VERSION ""

NS_ :

BS_:

BU_: APM CanBlue Car_PC BMS DCDC SCU BRS_ECU

BO_ 3221225472 VECTOR__INDEPENDENT_SIG_MSG: 0 Vector__XXX
 SG_ MASTER_ESA_CheckSum : 0|8@0+ (1,0) [0|255] "" Vector__XXX
 SG_ MASTER_REQ_CheckSum : 0|8@0+ (1,0) [0|255] "" Vector__XXX
 SG_ New_Signal_263 : 0|8@1+ (1,0) [0|0] "" Vector__XXX
 SG_ New_Signal_262 : 0|8@1+ (1,0) [0|0] "" Vector__XXX
 SG_ VehV_a : 0|16@0- (0.001,0) [-32.768|32.767] "" Vector__XXX

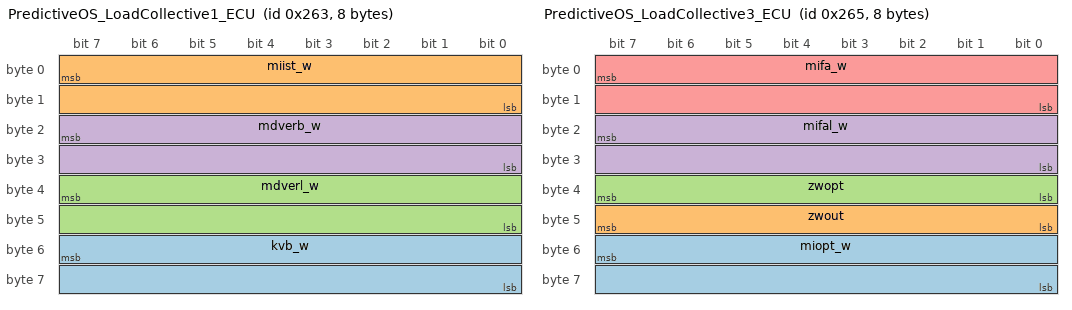
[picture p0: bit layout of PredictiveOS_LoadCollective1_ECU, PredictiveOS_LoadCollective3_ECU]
BO_ 611 PredictiveOS_LoadCollective1_ECU: 8 BRS_ECU
 SG_ kvb_w : 55|16@0+ (0.00390625,0) [0|255.99609375] "" Vector__XXX
 SG_ miist_w : 7|16@0+ (0.00152587890625,0) [0|99.9984741210938] "%" Vector__XXX
 SG_ mdverl_w : 39|16@0+ (0.00152587890625,0) [0|99.9984741210938] "%" Vector__XXX
 SG_ mdverb_w : 23|16@0+ (0.00152587890625,0) [0|99.9984741210938] "%" Vector__XXX

BO_ 384 SAS_180_CAN1: 8 Vector__XXX
 SG_ SAS_SteeringAngle : 7|16@0- (0.1,-780) [-1320|-240] "degree"  BRS_ECU

BO_ 304 ID1_CAN2: 8 Vector__XXX
 SG_ IMU_YawRt : 0|16@1+ (0.005,-163.84) [-163.84|163.84] "degree/s"  BRS_ECU

BO_ 613 PredictiveOS_LoadCollective3_ECU: 8 BRS_ECU
 SG_ miopt_w : 55|16@0+ (0.00152587890625,0) [0|99.9984741210938] "%" Vector__XXX
 SG_ zwout : 47|8@0- (0.75,0) [-96|95.25] "" Vector__XXX
 SG_ zwopt : 39|8@0- (0.75,0) [-96|95.25] "Grad KW" Vector__XXX
 SG_ mifal_w : 23|16@0+ (0.00152587890625,0) [0|99.9984741210938] "%" Vector__XXX
 SG_ mifa_w : 7|16@0+ (0.00152587890625,0) [0|99.9984741210938] "%" Vector__XXX

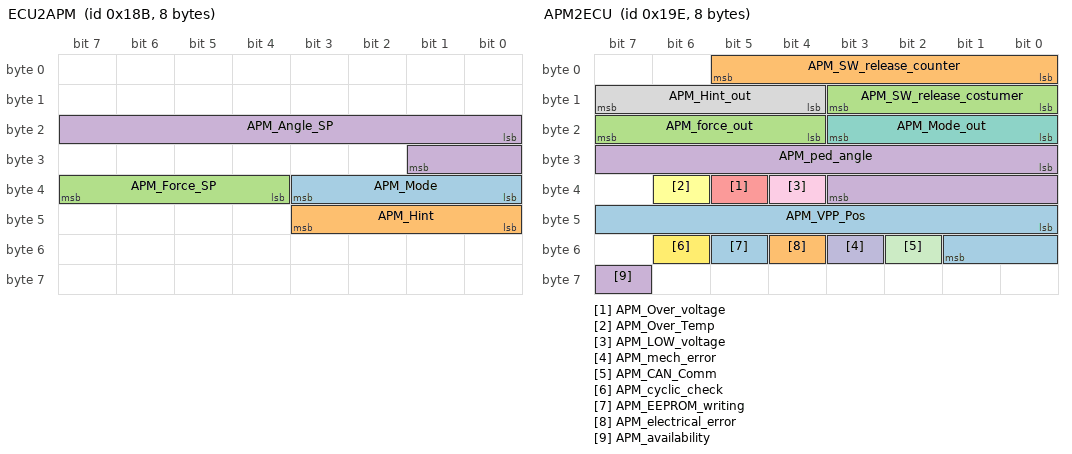
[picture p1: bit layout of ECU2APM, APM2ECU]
BO_ 395 ECU2APM: 8 BRS_ECU
 SG_ APM_Mode : 32|4@1+ (1,0) [0|15] ""  APM
 SG_ APM_Hint : 40|4@1+ (1,0) [0|15] ""  APM
 SG_ APM_Force_SP : 36|4@1+ (2,0) [0|30] "Unit_Newto"  APM
 SG_ APM_Angle_SP : 16|10@1+ (0.13004,-19.89612) [0|100.00076] "Unit_PerCent"  APM

BO_ 414 APM2ECU: 8 APM
 SG_ APM_VPP_Pos : 40|10@1+ (0.13004,-19.89612) [0|100.00076] "Unit_PerCent"  BRS_ECU
 SG_ APM_SW_release_counter : 0|6@1- (1,0) [0|0] ""  BRS_ECU
 SG_ APM_SW_release_costumer : 8|4@1- (1,0) [0|0] ""  BRS_ECU
 SG_ APM_ped_angle : 24|12@1+ (0.03253569,-19.97691366) [0|113.25673689] "Unit_PerCent"  BRS_ECU
 SG_ APM_Over_voltage : 37|1@1+ (1,0) [0|1] ""  BRS_ECU
 SG_ APM_Over_Temp : 38|1@1+ (1,0) [0|1] ""  BRS_ECU
 SG_ APM_Mode_out : 16|4@1+ (1,0) [0|15] ""  BRS_ECU
 SG_ APM_Hint_out : 12|4@1+ (1,0) [0|15] ""  BRS_ECU
 SG_ APM_LOW_voltage : 36|1@1+ (1,0) [0|1] ""  BRS_ECU
 SG_ APM_mech_error : 51|1@1+ (1,0) [0|1] ""  BRS_ECU
 SG_ APM_CAN_Comm : 50|1@1+ (1,0) [0|1] ""  BRS_ECU
 SG_ APM_cyclic_check : 54|1@1+ (1,0) [0|1] ""  BRS_ECU
 SG_ APM_EEPROM_writing : 53|1@1+ (1,0) [0|1] ""  BRS_ECU
 SG_ APM_electrical_error : 52|1@1+ (1,0) [0|1] ""  BRS_ECU
 SG_ APM_force_out : 20|4@1+ (2,0) [0|30] "Unit_Newto"  BRS_ECU
 SG_ APM_availability : 63|1@1+ (1,0) [0|1] ""  BRS_ECU

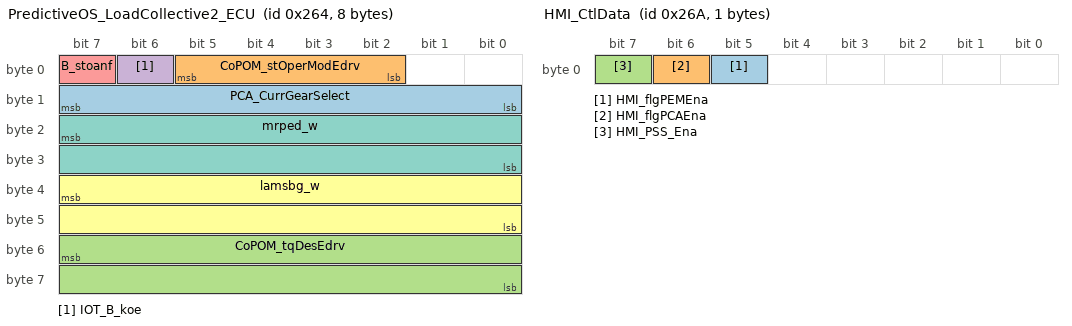
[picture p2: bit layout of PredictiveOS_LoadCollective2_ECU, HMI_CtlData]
BO_ 612 PredictiveOS_LoadCollective2_ECU: 8 BRS_ECU
 SG_ PCA_CurrGearSelect : 15|8@0+ (1,-1) [-1|254] "" Vector__XXX
 SG_ CoPOM_stOperModEdrv : 5|4@0+ (1,0) [0|7] "" Vector__XXX
 SG_ CoPOM_tqDesEdrv : 55|16@0- (0.1,0) [-3276.8|3276.7] "Nm" Vector__XXX
 SG_ IOT_B_koe : 6|1@0+ (1,0) [0|1] "" Vector__XXX
 SG_ B_stoanf : 7|1@0+ (1,0) [0|1] "" Vector__XXX
 SG_ lamsbg_w : 39|16@0+ (0.000244140625,0) [0|15.999755859375] "" Vector__XXX
 SG_ mrped_w : 23|16@0+ (0.0030517578125,0) [0|199.996948242188] "%" Vector__XXX

BO_ 618 HMI_CtlData: 1 CanBlue
 SG_ HMI_flgPEMEna : 5|1@0+ (1,0) [0|1] ""  BRS_ECU
 SG_ HMI_flgPCAEna : 6|1@0+ (1,0) [0|1] ""  BRS_ECU
 SG_ HMI_PSS_Ena : 7|1@0+ (1,0) [0|1] ""  BRS_ECU

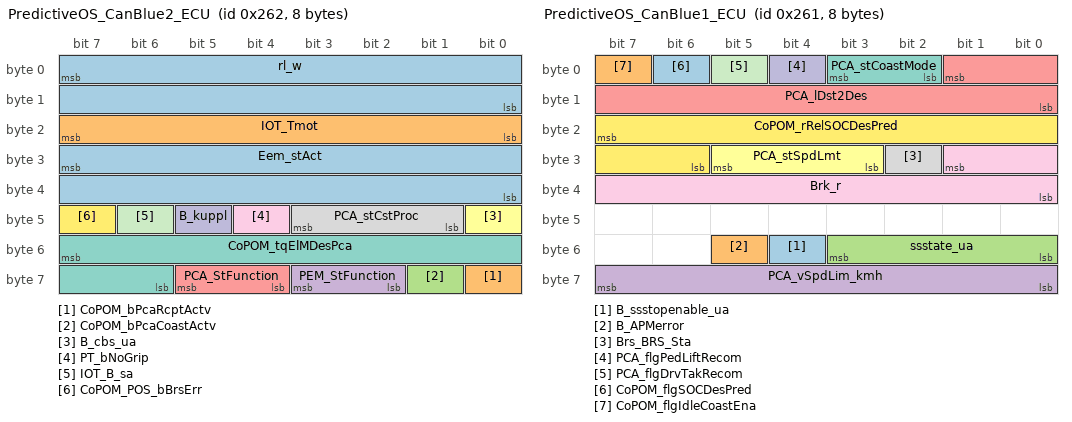
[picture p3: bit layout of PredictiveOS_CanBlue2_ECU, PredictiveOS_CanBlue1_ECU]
BO_ 610 PredictiveOS_CanBlue2_ECU: 8 BRS_ECU
 SG_ rl_w : 7|16@0+ (0.0234375,0) [0|1535.9765625] "%"  CanBlue
 SG_ CoPOM_bPcaRcptActv : 56|1@0+ (1,0) [0|1] ""  CanBlue
 SG_ CoPOM_bPcaCoastActv : 57|1@0+ (1,0) [0|1] ""  CanBlue
 SG_ PEM_StFunction : 59|2@0+ (1,0) [0|3] ""  CanBlue
 SG_ PCA_StFunction : 61|2@0+ (1,0) [0|3] ""  CanBlue
 SG_ B_cbs_ua : 40|1@0+ (1,0) [0|1] ""  CanBlue
 SG_ CoPOM_tqElMDesPca : 55|10@0+ (0.1,-50) [-50|0] ""  CanBlue
 SG_ PCA_stCstProc : 43|3@0+ (1,0) [0|7] ""  CanBlue
 SG_ PT_bNoGrip : 44|1@0+ (1,0) [0|1] ""  CanBlue
 SG_ B_kuppl : 45|1@0+ (1,0) [0|1] ""  CanBlue
 SG_ IOT_B_sa : 46|1@0+ (1,0) [0|1] ""  CanBlue
 SG_ CoPOM_POS_bBrsErr : 47|1@0+ (1,0) [0|1] ""  CanBlue
 SG_ Eem_stAct : 31|16@0+ (1,0) [0|56636] ""  CanBlue
 SG_ IOT_Tmot : 23|8@0+ (0.75,-48) [-48|143.25] ""  CanBlue

BO_ 609 PredictiveOS_CanBlue1_ECU: 8 BRS_ECU
 SG_ B_ssstopenable_ua : 52|1@0+ (1,0) [0|1] "" Vector__XXX
 SG_ B_APMerror : 53|1@0+ (1,0) [0|1] "" Vector__XXX
 SG_ ssstate_ua : 51|4@0+ (1,0) [0|6] "" Vector__XXX
 SG_ PCA_vSpdLim_kmh : 63|8@0+ (1,0) [0|255] ""  CanBlue
 SG_ PCA_lDst2Des : 1|10@0+ (1,0) [0|1000] ""  CanBlue
 SG_ PCA_stSpdLmt : 29|3@0+ (1,0) [0|7] ""  CanBlue
 SG_ PCA_stCoastMode : 3|2@0+ (1,0) [0|3] ""  CanBlue
 SG_ Brs_BRS_Sta : 26|1@0+ (1,0) [0|1] ""  CanBlue
 SG_ Brk_r : 25|10@0+ (0.1,0) [0|100] ""  CanBlue
 SG_ PCA_flgPedLiftRecom : 4|1@0+ (1,0) [0|1] ""  CanBlue
 SG_ PCA_flgDrvTakRecom : 5|1@0+ (1,0) [0|1] ""  CanBlue
 SG_ CoPOM_rRelSOCDesPred : 23|10@0+ (0.1,0) [0|100] ""  CanBlue
 SG_ CoPOM_flgSOCDesPred : 6|1@0+ (1,0) [0|1] ""  CanBlue
 SG_ CoPOM_flgIdleCoastEna : 7|1@0+ (1,0) [0|1] ""  CanBlue

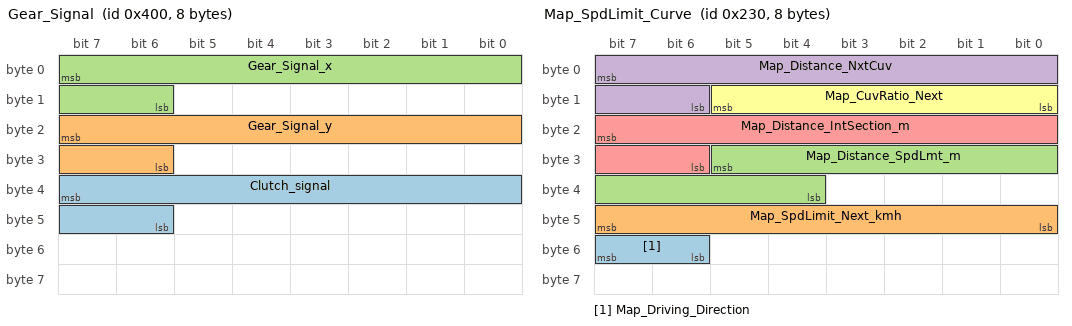
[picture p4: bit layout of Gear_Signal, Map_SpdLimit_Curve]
BO_ 1024 Gear_Signal: 8 Vector__XXX
 SG_ Clutch_signal : 39|10@0+ (1,0) [0|1023] ""  BRS_ECU
 SG_ Gear_Signal_y : 23|10@0+ (1,0) [0|1023] ""  BRS_ECU
 SG_ Gear_Signal_x : 7|10@0+ (1,0) [0|1023] ""  BRS_ECU

BO_ 560 Map_SpdLimit_Curve: 8 Car_PC
 SG_ Map_Driving_Direction : 55|2@0+ (1,0) [0|2] ""  BRS_ECU
 SG_ Map_SpdLimit_Next_kmh : 47|8@0+ (1,0) [0|255] "kmh"  BRS_ECU
 SG_ Map_Distance_SpdLmt_m : 29|10@0+ (1,0) [0|1023] "m"  BRS_ECU
 SG_ Map_Distance_NxtCuv : 7|10@0+ (1,0) [0|1023] "m"  BRS_ECU
 SG_ Map_Distance_IntSection_m : 23|10@0+ (1,0) [0|1023] "m"  BRS_ECU
 SG_ Map_CuvRatio_Next : 13|6@0+ (0.5,0) [0|63] "m"  BRS_ECU

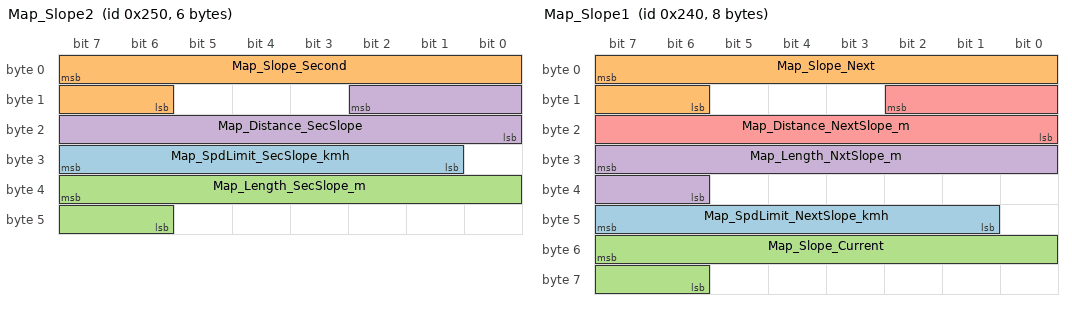
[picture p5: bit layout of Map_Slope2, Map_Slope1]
BO_ 592 Map_Slope2: 6 Car_PC
 SG_ Map_SpdLimit_SecSlope_kmh : 31|7@0+ (1,0) [0|127] "kmh"  BRS_ECU
 SG_ Map_Slope_Second : 7|10@0+ (0.1,-50) [-50|50] "degree"  BRS_ECU
 SG_ Map_Length_SecSlope_m : 39|10@0+ (1,0) [0|1023] "m"  BRS_ECU
 SG_ Map_Distance_SecSlope : 10|11@0+ (1,0) [0|2047] "m"  BRS_ECU

BO_ 576 Map_Slope1: 8 Car_PC
 SG_ Map_SpdLimit_NextSlope_kmh : 47|7@0+ (1,0) [0|127] "kmh"  BRS_ECU
 SG_ Map_Slope_Next : 7|10@0+ (0.1,-50) [-50|50] "degree"  BRS_ECU
 SG_ Map_Slope_Current : 55|10@0+ (0.1,-50) [-50|50] "degree"  BRS_ECU
 SG_ Map_Length_NxtSlope_m : 31|10@0+ (1,0) [0|1023] "m"  BRS_ECU
 SG_ Map_Distance_NextSlope_m : 10|11@0+ (1,0) [0|2047] "m"  BRS_ECU

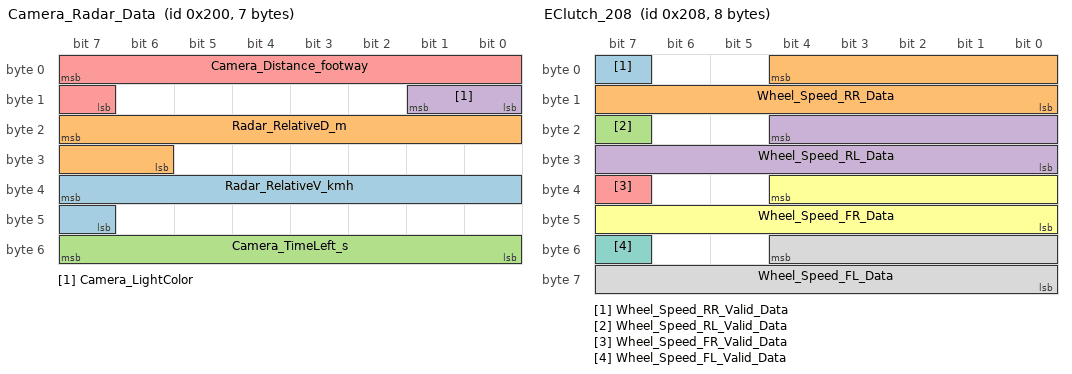
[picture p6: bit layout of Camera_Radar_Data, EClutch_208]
BO_ 512 Camera_Radar_Data: 7 Car_PC
 SG_ Radar_RelativeV_kmh : 39|9@0+ (0.5,-128) [-128|127] "km/h"  BRS_ECU
 SG_ Radar_RelativeD_m : 23|10@0+ (0.5,0) [0|250] "m"  BRS_ECU
 SG_ Camera_TimeLeft_s : 55|8@0+ (1,0) [0|60] "s"  BRS_ECU
 SG_ Camera_LightColor : 9|2@0+ (1,0) [0|3] ""  BRS_ECU
 SG_ Camera_Distance_footway : 7|9@0+ (0.5,0) [0|255] "m"  BRS_ECU

BO_ 520 EClutch_208: 8 BRS_ECU
 SG_ Wheel_Speed_RR_Valid_Data : 7|1@0+ (1,0) [0|1] "" Vector__XXX
 SG_ Wheel_Speed_RR_Data : 4|13@0+ (0.05625,0) [0|360] "" Vector__XXX
 SG_ Wheel_Speed_RL_Valid_Data : 23|1@0+ (1,0) [0|1] "" Vector__XXX
 SG_ Wheel_Speed_RL_Data : 20|13@0+ (0.05625,0) [0|360] "km/h" Vector__XXX
 SG_ Wheel_Speed_FR_Valid_Data : 39|1@0+ (1,0) [0|1] "" Vector__XXX
 SG_ Wheel_Speed_FR_Data : 36|13@0+ (0.05625,0) [0|360] "" Vector__XXX
 SG_ Wheel_Speed_FL_Valid_Data : 55|1@0+ (1,0) [0|1] "" Vector__XXX
 SG_ Wheel_Speed_FL_Data : 52|13@0+ (0.05625,0) [0|360] "km/h" Vector__XXX

BO_ 597 EClutch_255: 8 BRS_ECU
 SG_ EMS_AccPedal : 47|8@0+ (0.392,0) [0|99.96] "%" Vector__XXX
 SG_ EMS_ThrottleValvePositionError : 11|1@0+ (1,0) [0|1] "" Vector__XXX
 SG_ EMS_RollingCounter_id255 : 59|4@0+ (1,0) [0|15] "" Vector__XXX
 SG_ EMS_KickDown : 15|1@0+ (1,0) [0|1] "" Vector__XXX
 SG_ EMS_IntakeAirTempSensorError : 8|1@0+ (1,0) [0|1] "" Vector__XXX
 SG_ EMS_EngineThrottlePosition : 39|8@0+ (0.392,0) [0|99.96] "%" Vector__XXX
 SG_ EMS_EngineSpeedError : 12|1@0+ (1,0) [0|1] "" Vector__XXX
 SG_ EMS_EngineSpeed : 23|16@0+ (0.25,0) [0|16383.5] "Rpm" Vector__XXX
 SG_ EMS_EngineIntakeAirTemp : 55|8@0+ (0.75,-40) [-40|150.5] "" Vector__XXX
 SG_ EMS_EngineFuelCutOff : 14|1@0+ (1,0) [0|1] "" Vector__XXX
 SG_ EMS_CruiseControlStatus : 1|2@0+ (1,0) [0|3] "" Vector__XXX
 SG_ EMS_ConditionIdle : 5|1@0+ (1,0) [0|1] "" Vector__XXX
 SG_ EMS_CompressorStatus : 4|1@0+ (1,0) [0|1] "" Vector__XXX
 SG_ EMS_ClutchPedalStatus : 3|2@0+ (1,0) [0|3] "" Vector__XXX
 SG_ EMS_CheckSum_255 : 63|4@0+ (1,0) [0|0] "" Vector__XXX
 SG_ EMS_BrakePedalStatus : 7|2@0+ (1,0) [0|3] "" Vector__XXX
 SG_ EMS_AccpedelError : 10|1@0+ (1,0) [0|1] "" Vector__XXX

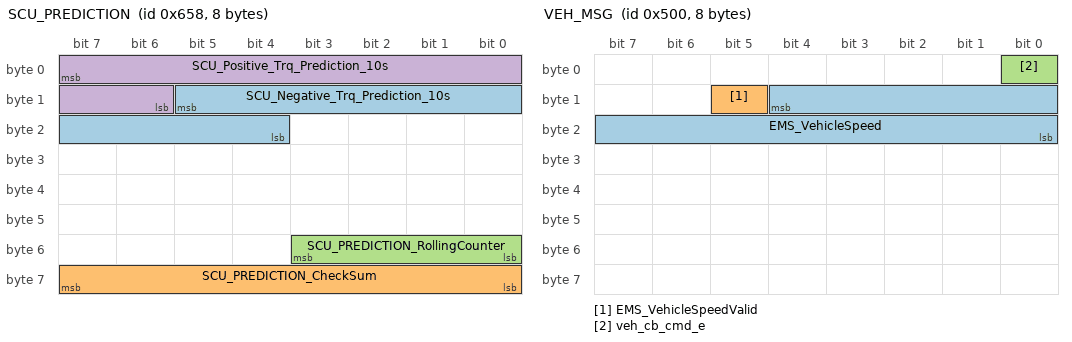
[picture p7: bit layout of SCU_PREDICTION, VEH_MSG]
BO_ 1624 SCU_PREDICTION: 8 SCU
 SG_ SCU_Negative_Trq_Prediction_10s : 13|10@0+ (0.1,-55) [-55|0] ""  BRS_ECU
 SG_ SCU_PREDICTION_CheckSum : 63|8@0+ (1,0) [0|255] ""  BRS_ECU
 SG_ SCU_PREDICTION_RollingCounter : 51|4@0+ (1,0) [0|15] ""  BRS_ECU
 SG_ SCU_Positive_Trq_Prediction_10s : 7|10@0+ (0.1,0) [0|55] "NM"  BRS_ECU

BO_ 1367 EMS_557: 8 BRS_ECU
 SG_ EMS_TotalOdometer : 7|18@0+ (5,0) [0|1310710] ""  SCU

BO_ 1621 SCU_DIAG: 8 SCU
 SG_ SCU_12V_VOLTAGE_LOW : 36|1@0+ (1,0) [0|1] ""  BRS_ECU
 SG_ SCU_REVERSE_SPEED_FAULT : 35|1@0+ (1,0) [0|1] ""  BRS_ECU
 SG_ SCU_12V_VOLTAGE_HIGH : 37|1@0+ (1,0) [0|1] ""  BRS_ECU
 SG_ SCU_BUSOFF_FAULT : 38|1@0+ (1,0) [0|1] ""  BRS_ECU
 SG_ SCU_UNLOCK_PTL_FAULT : 20|1@0+ (1,0) [0|1] ""  BRS_ECU
 SG_ SCU_DIAG_RollingCounter : 51|4@0+ (1,0) [0|15] ""  BRS_ECU
 SG_ SCU_DIAG_CheckSum : 63|8@0+ (1,0) [0|255] ""  BRS_ECU
 SG_ SCU_BRUSH_WEAR_FAULT : 27|1@0+ (1,0) [0|1] ""  BRS_ECU
 SG_ SCU_EXC_OPENCIRCUIT_FAULT : 39|1@0+ (1,0) [0|1] ""  BRS_ECU
 SG_ SCU_EXC_LATENT_FAULT : 24|1@0+ (1,0) [0|1] ""  BRS_ECU
 SG_ SCU_EXC_HSM_FAULT : 25|1@0+ (1,0) [0|1] ""  BRS_ECU
 SG_ SCU_CAN_COM_ERROR : 26|1@0+ (1,0) [0|1] ""  BRS_ECU
 SG_ SCU_DC_VOLTAGEMEAS_SENSOR_FAULT : 28|1@0+ (1,0) [0|1] ""  BRS_ECU
 SG_ SCU_PHX_CURRENT_SENSOR_FAULT : 17|3@0+ (1,0) [0|6] ""  BRS_ECU
 SG_ SCU_MACHINE_TEMP_SENSOR_FAULT : 18|1@0+ (1,0) [0|1] ""  BRS_ECU
 SG_ SCU_INVERTER_TEMP_SENSOR_FAULT : 19|1@0+ (1,0) [0|1] ""  BRS_ECU
 SG_ SCU_POSITION_SENSORS_FAULT : 21|1@0+ (1,0) [0|1] ""  BRS_ECU
 SG_ SCU_STATOR_FAULT : 22|1@0+ (1,0) [0|1] ""  BRS_ECU
 SG_ SCU_INVERTER_FAULT : 23|1@0+ (1,0) [0|1] ""  BRS_ECU
 SG_ SCU_TORQUE_CTRL_TIMEOUT : 8|1@0+ (1,0) [0|1] ""  BRS_ECU
 SG_ SCU_TORQUE_SIGN_FAULT : 9|1@0+ (1,0) [0|1] ""  BRS_ECU
 SG_ SCU_TORQUE_LEVEL_FAULT : 10|1@0+ (1,0) [0|1] ""  BRS_ECU
 SG_ SCU_ROTOR_OVERCURRENT : 11|1@0+ (1,0) [0|1] ""  BRS_ECU
 SG_ SCU_STATOR_OVERCURRENT : 14|3@0+ (1,0) [0|6] ""  BRS_ECU
 SG_ SCU_LOADDUMP : 15|1@0+ (1,0) [0|1] ""  BRS_ECU
 SG_ SCU_OVERVOLTAGE : 0|1@0+ (1,0) [0|1] ""  BRS_ECU
 SG_ SCU_MOSFET_JUNCTION_PROTECTION : 1|1@0+ (1,0) [0|1] ""  BRS_ECU
 SG_ SCU_OVERHEATING : 2|1@0+ (1,0) [0|1] ""  BRS_ECU
 SG_ SCU_STARTER_WARNING : 3|1@0+ (1,0) [0|1] ""  BRS_ECU
 SG_ SCU_THERMAL_DERATING : 4|1@0+ (1,0) [0|1] ""  BRS_ECU
 SG_ SCU_STALLED_ROTOR_PROTECTION : 6|1@0+ (1,0) [0|1] ""  BRS_ECU
 SG_ SCU_TORQUE_SUSPENSION : 7|1@0+ (1,0) [0|1] ""  BRS_ECU

BO_ 1280 VEH_MSG: 8 BRS_ECU
 SG_ EMS_VehicleSpeed : 12|13@0+ (0.05625,0) [0|360] "km/h"  BMS
 SG_ EMS_VehicleSpeedValid : 13|1@0+ (1,0) [0|1] ""  BMS
 SG_ veh_cb_cmd_e : 0|1@0+ (1,0) [0|1] ""  BMS

BO_ 1536 PACK_STATUS_1: 7 BMS
 SG_ BMS_fan_err_actv_b : 55|1@0+ (1,0) [0|1] ""  BRS_ECU
 SG_ dtc_cbuvp_dschrg_open_actv_b : 52|1@0+ (1,0) [0|1] ""  BRS_ECU
 SG_ dtc_cbovp_chrg_open_actv_b : 53|1@0+ (1,0) [0|1] ""  BRS_ECU
 SG_ dtc_cb_unexpected_open_actv_b : 51|1@0+ (1,0) [0|1] ""  BRS_ECU
 SG_ dtc_cb_otp_actv_b : 54|1@0+ (1,0) [0|1] ""  BRS_ECU
 SG_ stack_U_samplingfault_actv_b : 43|1@0+ (1,0) [0|1] ""  BRS_ECU
 SG_ rom_fault_actv_b : 27|1@0+ (1,0) [0|1] ""  BRS_ECU
 SG_ rolling_counter : 3|4@0+ (1,0) [0|15] ""  BRS_ECU
 SG_ ram_fault_actv_b : 28|1@0+ (1,0) [0|1] ""  BRS_ECU
 SG_ pwr_uvp_actv_b : 38|1@0+ (1,0) [0|1] ""  BRS_ECU
 SG_ pwr_ovp_actv_b : 39|1@0+ (1,0) [0|1] ""  BRS_ECU
 SG_ pack_uvp_actv_b : 34|1@0+ (1,0) [0|1] ""  BRS_ECU
 SG_ pack_T_samplingfault_actv_b : 40|1@0+ (1,0) [0|1] ""  BRS_ECU
 SG_ pack_ovp_actv_b : 35|1@0+ (1,0) [0|1] ""  BRS_ECU
 SG_ pack_deep_chrg_b : 47|1@0+ (1,0) [0|1] ""  BRS_ECU
 SG_ otp_actv_b : 33|1@0+ (1,0) [0|1] ""  BRS_ECU
 SG_ ocp_actv_b : 32|1@0+ (1,0) [0|1] ""  BRS_ECU
 SG_ inst_I_samplingfault_actv_b : 41|1@0+ (1,0) [0|1] ""  BRS_ECU
 SG_ ecu_comm_fault_actv_b : 29|1@0+ (1,0) [0|1] ""  BRS_ECU
 SG_ dtc_equalize_fail_actv_b : 49|1@0+ (1,0) [0|1] ""  BRS_ECU
 SG_ dtc_cb_weld_actv_b : 48|1@0+ (1,0) [0|1] ""  BRS_ECU
 SG_ dtc_cb_stuck_open_actv_b : 50|1@0+ (1,0) [0|1] ""  BRS_ECU
 SG_ cell_uvp_act_b : 36|1@0+ (1,0) [0|1] ""  BRS_ECU
 SG_ cell_U_samplingfault_actv_b : 42|1@0+ (1,0) [0|1] ""  BRS_ECU
 SG_ cell_ovp_actv_b : 37|1@0+ (1,0) [0|1] ""  BRS_ECU
 SG_ cell_deep_dschrg_b : 44|1@0+ (1,0) [0|1] ""  BRS_ECU
 SG_ cell_deep_chrg_b : 45|1@0+ (1,0) [0|1] ""  BRS_ECU
 SG_ can_busoff_actv_b : 25|1@0+ (1,0) [0|1] ""  BRS_ECU
 SG_ bcc_fault_actv_b : 30|1@0+ (1,0) [0|1] ""  BRS_ECU
 SG_ bcc_comm_fault_actv_b : 31|1@0+ (1,0) [0|1] ""  BRS_ECU
 SG_ cbal_en_b : 24|1@0+ (1,0) [0|1] ""  BRS_ECU
 SG_ pack_deep_dschrg_b : 46|1@0+ (1,0) [0|1] ""  BRS_ECU
 SG_ nvm_fault_actv_b : 26|1@0+ (1,0) [0|1] ""  BRS_ECU
 SG_ cb_state_e : 6|3@0+ (1,0) [0|7] ""  BRS_ECU

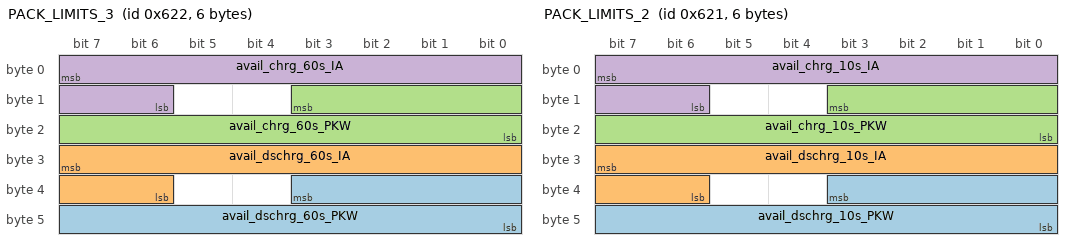
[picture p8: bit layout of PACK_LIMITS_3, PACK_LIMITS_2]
BO_ 1570 PACK_LIMITS_3: 6 BMS
 SG_ avail_dschrg_60s_PKW : 35|12@0+ (0.01,-40.95) [-40.95|0] "KW"  BRS_ECU
 SG_ avail_dschrg_60s_IA : 31|10@0+ (1,-1023) [-1023|0] "A"  BRS_ECU
 SG_ avail_chrg_60s_PKW : 11|12@0+ (0.01,0) [0|40.95] "KW"  BRS_ECU
 SG_ avail_chrg_60s_IA : 7|10@0+ (1,0) [0|1023] "A"  BRS_ECU

BO_ 1569 PACK_LIMITS_2: 6 BMS
 SG_ avail_dschrg_10s_PKW : 35|12@0+ (0.01,-40.95) [-40.95|0] "KW"  BRS_ECU
 SG_ avail_dschrg_10s_IA : 31|10@0+ (1,-1023) [-1023|0] "A"  BRS_ECU
 SG_ avail_chrg_10s_PKW : 11|12@0+ (0.01,0) [0|40.95] "KW"  BRS_ECU
 SG_ avail_chrg_10s_IA : 7|10@0+ (1,0) [0|1023] "A"  BRS_ECU

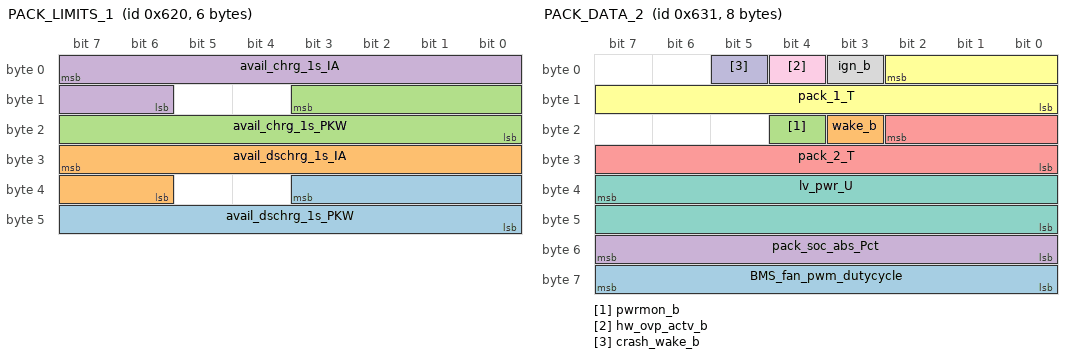
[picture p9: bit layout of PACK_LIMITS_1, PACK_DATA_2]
BO_ 1568 PACK_LIMITS_1: 6 BMS
 SG_ avail_dschrg_1s_PKW : 35|12@0+ (0.01,-40.95) [-40.95|0] "KW"  BRS_ECU
 SG_ avail_dschrg_1s_IA : 31|10@0+ (1,-1023) [-1023|0] "A"  BRS_ECU
 SG_ avail_chrg_1s_PKW : 11|12@0+ (0.01,0) [0|40.95] "KW"  BRS_ECU
 SG_ avail_chrg_1s_IA : 7|10@0+ (1,0) [0|1023] "A"  BRS_ECU

BO_ 1585 PACK_DATA_2: 8 BMS
 SG_ BMS_fan_pwm_dutycycle : 63|8@0+ (1,0) [0|100] "%"  BRS_ECU
 SG_ wake_b : 19|1@0+ (1,0) [0|1] ""  BRS_ECU
 SG_ pwrmon_b : 20|1@0+ (1,0) [0|1] ""  BRS_ECU
 SG_ pack_soc_abs_Pct : 55|8@0+ (1,0) [0|100] ""  BRS_ECU
 SG_ pack_2_T : 18|11@0+ (0.1,-40) [-40|140] "degC"  BRS_ECU
 SG_ pack_1_T : 2|11@0+ (0.1,-40) [-40|140] "degC"  BRS_ECU
 SG_ lv_pwr_U : 39|16@0+ (0.001,0) [0|65.535] "V"  BRS_ECU
 SG_ ign_b : 3|1@0+ (1,0) [0|1] ""  BRS_ECU
 SG_ hw_ovp_actv_b : 4|1@0+ (1,0) [0|1] ""  BRS_ECU
 SG_ crash_wake_b : 5|1@0+ (1,0) [0|1] ""  BRS_ECU

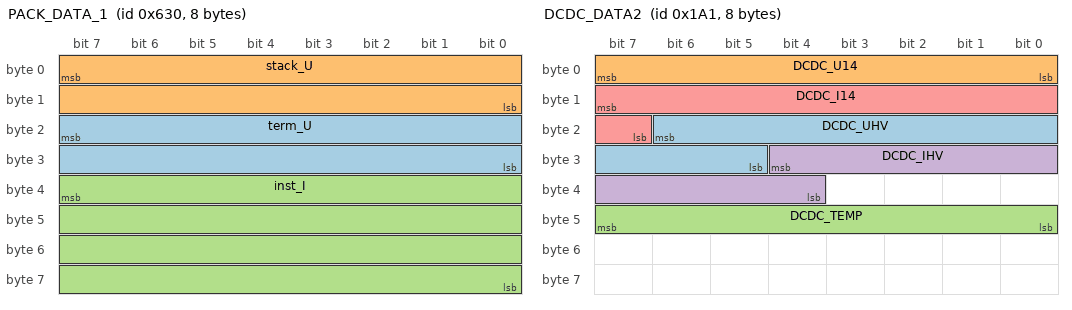
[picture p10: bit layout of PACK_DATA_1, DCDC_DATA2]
BO_ 1584 PACK_DATA_1: 8 BMS
 SG_ term_U : 23|16@0+ (0.001,0) [15|65] "V"  BRS_ECU
 SG_ stack_U : 7|16@0+ (0.001,0) [15|65] "V"  BRS_ECU
 SG_ inst_I : 39|32@0- (0.001,0) [0|0] "A"  BRS_ECU

BO_ 417 DCDC_DATA2: 8 DCDC
 SG_ DCDC_UHV : 22|10@0+ (0.1,0) [0|102.3] "V"  BRS_ECU
 SG_ DCDC_U14 : 7|8@0+ (0.1,0) [0|25.4] "V"  BRS_ECU
 SG_ DCDC_TEMP : 47|8@0+ (1,-48) [-48|206] "°C"  BRS_ECU
 SG_ DCDC_IHV : 28|9@0+ (1,-255) [-255|255] "A"  BRS_ECU
 SG_ DCDC_I14 : 15|9@0+ (1,-255) [-255|255] "A"  BRS_ECU

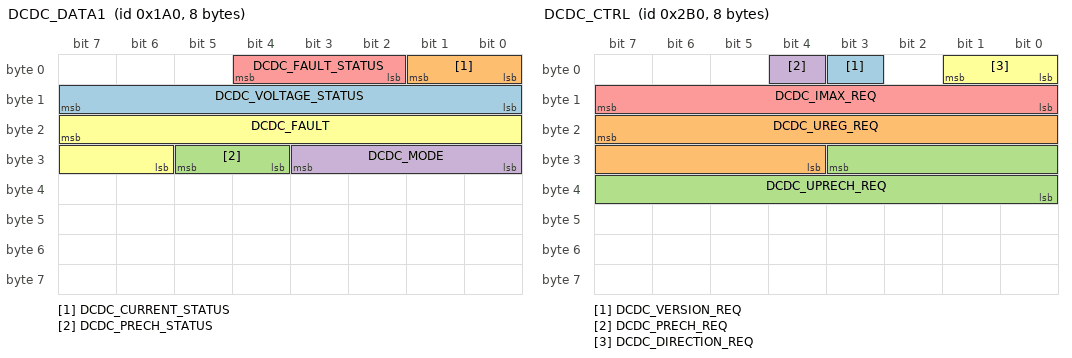
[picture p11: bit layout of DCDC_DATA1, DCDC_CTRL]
BO_ 416 DCDC_DATA1: 8 DCDC
 SG_ DCDC_VOLTAGE_STATUS : 15|8@0+ (1,0) [0|255] ""  BRS_ECU
 SG_ DCDC_CURRENT_STATUS : 1|2@0+ (1,0) [0|3] ""  BRS_ECU
 SG_ DCDC_PRECH_STATUS : 29|2@0+ (1,0) [0|3] ""  BRS_ECU
 SG_ DCDC_MODE : 27|4@0+ (1,0) [0|15] ""  BRS_ECU
 SG_ DCDC_FAULT_STATUS : 4|3@0+ (1,0) [0|7] ""  BRS_ECU
 SG_ DCDC_FAULT : 23|10@0+ (1,0) [0|1023] ""  BRS_ECU

BO_ 688 DCDC_CTRL: 8 BRS_ECU
 SG_ DCDC_VERSION_REQ : 3|1@0+ (1,0) [0|1] ""  DCDC
 SG_ DCDC_UREG_REQ : 23|12@0+ (0.015,0) [0|61.425] "V"  DCDC
 SG_ DCDC_UPRECH_REQ : 27|12@0+ (0.015,0) [0|61.41] "V"  DCDC
 SG_ DCDC_PRECH_REQ : 4|1@0+ (1,0) [0|1] ""  DCDC
 SG_ DCDC_IMAX_REQ : 15|8@0+ (1,0) [0|255] "A"  DCDC
 SG_ DCDC_DIRECTION_REQ : 1|2@0+ (1,0) [0|3] ""  DCDC

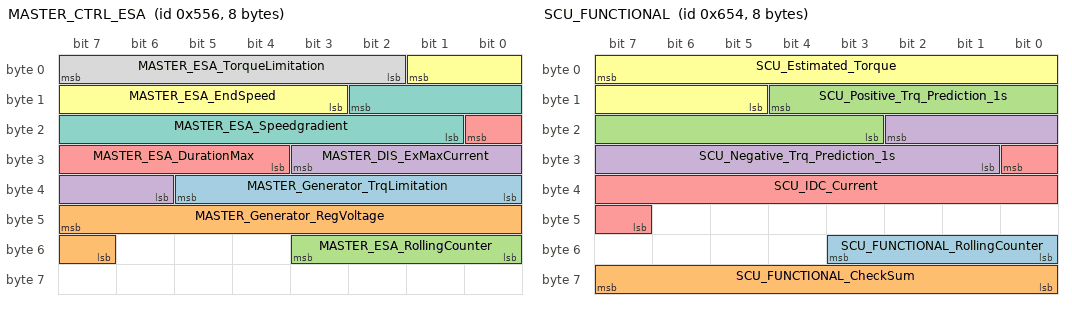
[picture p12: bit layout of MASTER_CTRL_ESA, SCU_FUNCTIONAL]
BO_ 1366 MASTER_CTRL_ESA: 8 BRS_ECU
 SG_ MASTER_Generator_TrqLimitation : 37|6@0+ (-1,0) [-30|0] "Nm"  SCU
 SG_ MASTER_Generator_RegVoltage : 47|9@0+ (0.1,10) [20|54] "V"  SCU
 SG_ MASTER_ESA_RollingCounter : 51|4@0+ (1,0) [0|15] ""  SCU
 SG_ MASTER_DIS_ExMaxCurrent : 27|6@0+ (0.1,0) [0|5] "A"  SCU
 SG_ MASTER_ESA_DurationMax : 16|5@0+ (0.1,0) [0|2] "s"  SCU
 SG_ MASTER_ESA_EndSpeed : 1|7@0+ (10,0) [0|1000] "Rpm"  SCU
 SG_ MASTER_ESA_Speedgradient : 10|10@0+ (-10,0) [-8000|0] "Rpm/s"  SCU
 SG_ MASTER_ESA_TorqueLimitation : 7|6@0+ (-1,0) [-44|0] "Nm"  SCU

BO_ 1620 SCU_FUNCTIONAL: 8 SCU
 SG_ SCU_FUNCTIONAL_RollingCounter : 51|4@0+ (1,0) [0|15] ""  BRS_ECU
 SG_ SCU_FUNCTIONAL_CheckSum : 63|8@0+ (1,0) [0|255] ""  BRS_ECU
 SG_ SCU_Positive_Trq_Prediction_1s : 12|10@0+ (0.1,0) [0|55] "Nm"  BRS_ECU
 SG_ SCU_Negative_Trq_Prediction_1s : 18|10@0+ (-0.1,0) [-55|0] "Nm"  BRS_ECU
 SG_ SCU_IDC_Current : 24|10@0+ (1,-400) [-400|400] "A"  BRS_ECU
 SG_ SCU_Estimated_Torque : 7|11@0+ (0.1,-55) [-55|55] "Nm"  BRS_ECU

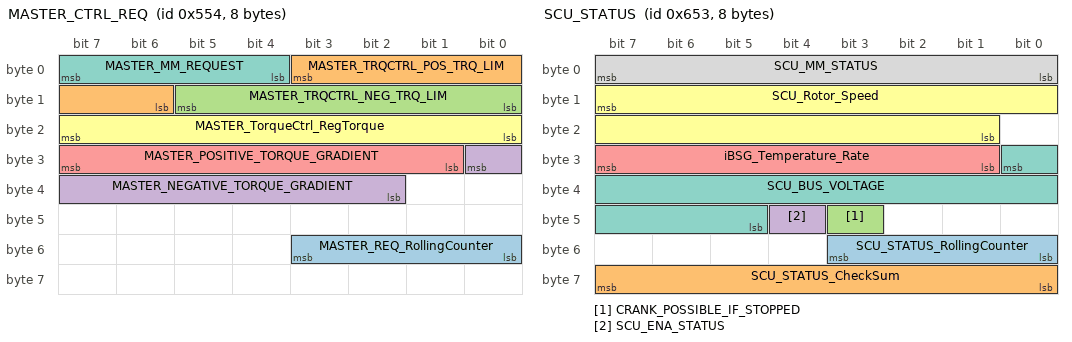
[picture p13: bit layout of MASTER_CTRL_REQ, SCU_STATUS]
BO_ 1364 MASTER_CTRL_REQ: 8 BRS_ECU
 SG_ MASTER_REQ_RollingCounter : 51|4@0+ (1,0) [0|15] ""  SCU
 SG_ MASTER_TRQCTRL_POS_TRQ_LIM : 3|6@0+ (1,0) [0|55] "Nm"  SCU
 SG_ MASTER_TRQCTRL_NEG_TRQ_LIM : 13|6@0+ (-1,0) [-44|0] "Nm"  SCU
 SG_ MASTER_NEGATIVE_TORQUE_GRADIENT : 24|7@0+ (-10,0) [-1000|0] "Nm/s"  SCU
 SG_ MASTER_POSITIVE_TORQUE_GRADIENT : 31|7@0+ (10,0) [0|1000] "Nm/s"  SCU
 SG_ MASTER_TorqueCtrl_RegTorque : 23|8@0+ (0.5,-44) [-44|55] "Nm"  SCU
 SG_ MASTER_MM_REQUEST : 7|4@0+ (1,0) [1|8] ""  SCU

BO_ 1619 SCU_STATUS: 8 SCU
 SG_ SCU_STATUS_RollingCounter : 51|4@0+ (1,0) [0|15] ""  BRS_ECU
 SG_ SCU_STATUS_CheckSum : 63|8@0+ (1,0) [0|255] ""  BRS_ECU
 SG_ CRANK_POSSIBLE_IF_STOPPED : 43|1@0+ (1,0) [0|1] ""  BRS_ECU
 SG_ SCU_ENA_STATUS : 44|1@0+ (1,0) [0|1] ""  BRS_ECU
 SG_ iBSG_Temperature_Rate : 31|7@0+ (1,0) [0|120] "%"  BRS_ECU
 SG_ SCU_Rotor_Speed : 15|15@0+ (1,-2000) [-2000|22000] "Rpm"  BRS_ECU
 SG_ SCU_BUS_VOLTAGE : 24|12@0+ (0.02,0) [0|70] "V"  BRS_ECU
 SG_ SCU_MM_STATUS : 7|8@0+ (1,0) [16|131] ""  BRS_ECU

CM_ BO_ 3221225472 "This is a message for not used signals, created by Vector CANdb++ DBC OLE DB Provider.";
CM_ SG_ 3221225472 VehV_a "The acceleration of the vehicle";
CM_ SG_ 611 kvb_w "Consumed fuel";
CM_ SG_ 611 miist_w "Indicated real engine torque";
CM_ SG_ 611 mdverl_w "Resistant torque of the engine";
CM_ SG_ 611 mdverb_w "Torque request of the accessories";
CM_ SG_ 613 zwout "Ignition angle output value";
CM_ SG_ 613 zwopt "Optimized model reference ignition angle";
CM_ SG_ 613 mifal_w "Indicated driver's wish torque for torque coordination cylinder filling";
CM_ SG_ 613 mifa_w "Desired indicated engine torque";
CM_ SG_ 395 APM_Mode "Desired Mode
Sollmodus für Pedalwertbezogene Modi des Force Feedback Pedals
";
CM_ SG_ 395 APM_Hint "Desired Mode for hint feature
Sollvorgabe für Hinweisfeature";
CM_ SG_ 395 APM_Force_SP "Desired force setpoint of active feedback function";
CM_ SG_ 395 APM_Angle_SP "Desired pedal position of APM_Mode for force feedback pedal (e.g. postition of VPP)
Sollwert der Position für den Sollmodus des Forcefeedbackfahrpedals

Hinweis: Verfügbare Modi (Pedalwert bezogen) gemäß MO_FFP_Soll_Modus";
CM_ SG_ 414 APM_VPP_Pos "Gibt den aktuellen Winkel der Forcefeedbackeinheit des Pedals aus";
CM_ SG_ 414 APM_ped_angle "Gibt den aktuellen Fahrpedalwert aus (0 -100%)";
CM_ SG_ 414 APM_Over_voltage "Force Feedback Ueberspannung";
CM_ SG_ 414 APM_Over_Temp "Grenzwert Temperatur ForceFeedbackPedal erreicht";
CM_ SG_ 414 APM_Mode_out "aktueller pedalwertbezogener Modus des Force Feedback Pedals";
CM_ SG_ 414 APM_Hint_out "Ist Status Hinweisfeature";
CM_ SG_ 414 APM_LOW_voltage "Force Feedback Unterspannung";
CM_ SG_ 414 APM_mech_error "Force Feedback mechanischer Fehler";
CM_ SG_ 414 APM_CAN_Comm "Force Feedback Fehler CAN Kommunikation";
CM_ SG_ 414 APM_cyclic_check "Zyklusbit für alle kontinuierlichen Diagnosen";
CM_ SG_ 414 APM_EEPROM_writing "Zyklusbit für EEPROM-Diagnose";
CM_ SG_ 414 APM_electrical_error "Force Feedback electrical error";
CM_ SG_ 414 APM_force_out "aktuell aufgeschaltete Kraft des Force Feedback Pedals";
CM_ SG_ 414 APM_availability "Signalisiert Verfügbarkeit des Force Feedback Pedals";
CM_ SG_ 612 PCA_CurrGearSelect "Engaged gear";
CM_ SG_ 612 CoPOM_stOperModEdrv "0 - idle
1 - charge
2 - Reku
3 - Boost
4 - discharge";
CM_ SG_ 612 CoPOM_tqDesEdrv "Desired Electric drive torque.";
CM_ SG_ 612 IOT_B_koe "Condition for AC-compressor ON";
CM_ SG_ 612 mrped_w "Relative torque request by accelerator pedal";
CM_ SG_ 610 PEM_StFunction "01 PEM enable
10 PEM disable";
CM_ SG_ 610 PCA_StFunction "01 PCA Enable
10 PCA Disable";
CM_ SG_ 610 B_cbs_ua "Condition clutch sensor indicate clutch on bottom";
CM_ SG_ 610 IOT_B_sa "fuel off";
CM_ SG_ 609 B_ssstopenable_ua "0:not allow engine stop,
1:allow engine stop";
CM_ SG_ 609 PCA_stSpdLmt "1 TrafficLight Speed Limit
2 Curve Speed Limit
3 Speed limit sign
4 Front Vehicle speed limit";
CM_ SG_ 609 PCA_stCoastMode "stCstMode 0  No coast
                  1  Full Coasting
                  2  CR";
CM_ SG_ 560 Map_Driving_Direction "0  stright
1 turn left
2 turn right";
CM_ SG_ 560 Map_SpdLimit_Next_kmh "first next speed limit 
0xFF  Invalid value";
CM_ SG_ 560 Map_Distance_SpdLmt_m "distance to first next speed limit 
if  exceed detection scope,transmit max value
0x3FF  Invalid value";
CM_ SG_ 560 Map_Distance_NxtCuv " distance to next cuve
if  exceed detection scope,transmit max value
0x3FF  Invalid value
";
CM_ SG_ 560 Map_Distance_IntSection_m "Distance to next traffic light if Map can provide;
Distance to next IntSection if Map cannot provide traffic light info
if  exceed detection scope,transmit max value
0x3FF  Invalid value";
CM_ SG_ 560 Map_CuvRatio_Next " ratio of next cuve
0x3F  Invalid value";
CM_ SG_ 592 Map_SpdLimit_SecSlope_kmh "Second Down Slope Speed Limitation
0x7F  Invalid value
";
CM_ SG_ 592 Map_Slope_Second "Second slope 
Positive:uphill;Negative:Downhill
0x3FF  Invalid value";
CM_ SG_ 592 Map_Length_SecSlope_m "Length of second Slope 
0x3FF  Invalid value";
CM_ SG_ 592 Map_Distance_SecSlope "Distance to secondt slope
0x7FF  Invalid value";
CM_ SG_ 576 Map_SpdLimit_NextSlope_kmh "First Down Slope Speed Limitation
0x7F  Invalid value
";
CM_ SG_ 576 Map_Slope_Next "Next slope
Positive:uphill;Negative:Downhill
0x3FF  Invalid value";
CM_ SG_ 576 Map_Slope_Current "Current slope 
Positive:uphill;Negative:Downhill 0:level road
0x3FF  Invalid value";
CM_ SG_ 576 Map_Length_NxtSlope_m "Length of Next Slope
0x3FF  Invalid value";
CM_ SG_ 576 Map_Distance_NextSlope_m "
Distance to next slope
if  exceed detection scope,transmit max value 0x7FF ( Invalid value)";
CM_ SG_ 512 Radar_RelativeD_m "Distance to front vehicle in the same lane
0x3FF  Invalid value";
CM_ SG_ 512 Camera_TimeLeft_s "Left Time :
invalid value:0xFF
0:60 Normal";
CM_ SG_ 512 Camera_LightColor "Tarffic light color";
CM_ SG_ 512 Camera_Distance_footway "Distance to footway  by Camera recognization.
invalid value : 0x1FF";
CM_ BO_ 1621 "Signal description for Diagnostics";
CM_ SG_ 1621 SCU_EXC_OPENCIRCUIT_FAULT "Rotor open circuit detection";
CM_ SG_ 1621 SCU_EXC_LATENT_FAULT "Excitation circuit DMAG mosfet failure detection";
CM_ SG_ 1621 SCU_EXC_HSM_FAULT "Excitation circuit High side mosfet failure detection";
CM_ SG_ 1621 SCU_CAN_COM_ERROR "CAN fault detection";
CM_ SG_ 1621 SCU_DC_VOLTAGEMEAS_SENSOR_FAULT "+BAT48V Voltage sensor fault detection";
CM_ SG_ 1621 SCU_PHX_CURRENT_SENSOR_FAULT "Phase current sensor fault detection";
CM_ SG_ 1621 SCU_MACHINE_TEMP_SENSOR_FAULT "Temperature sensor fault detection on Stator";
CM_ SG_ 1621 SCU_INVERTER_TEMP_SENSOR_FAULT "Temperature sensor fault detection on Control board";
CM_ SG_ 1621 SCU_POSITION_SENSORS_FAULT "Power module failure detection in functional mode";
CM_ SG_ 1621 SCU_STATOR_FAULT "Power module failure detection in functional mode";
CM_ SG_ 1621 SCU_INVERTER_FAULT "Power module failure detection in functional mode";
CM_ SG_ 1621 SCU_TORQUE_CTRL_TIMEOUT "Torque control mode  timeout  detection at max current";
CM_ SG_ 1621 SCU_TORQUE_SIGN_FAULT "Unexpected torque sign detection";
CM_ SG_ 1621 SCU_TORQUE_LEVEL_FAULT "Unexpected torque level detection";
CM_ SG_ 1621 SCU_ROTOR_OVERCURRENT "Rotor over current detection in functional mode";
CM_ SG_ 1621 SCU_STATOR_OVERCURRENT "Functional Phase over current detection";
CM_ SG_ 1621 SCU_LOADDUMP "LOADDUMP detection on +BAT48V";
CM_ SG_ 1621 SCU_OVERVOLTAGE "Too high voltage detection on +BAT48V detection";
CM_ SG_ 1621 SCU_MOSFET_JUNCTION_PROTECTION "Power module junction temperature overheating  detection in functional mode";
CM_ SG_ 1621 SCU_OVERHEATING "Thermal overheating protection Flag for stator, rotor, Power module, Control Board and Excitation board";
CM_ SG_ 1621 SCU_STARTER_WARNING "Starter mode warning detection due to high temperature";
CM_ SG_ 1621 SCU_THERMAL_DERATING "Output Power Derating due to temperature";
CM_ SG_ 1621 SCU_STALLED_ROTOR_PROTECTION "Inverter thermal protection during cranking phase (stalled rotor)";
CM_ SG_ 1621 SCU_TORQUE_SUSPENSION "Negative speed detection in during a start attempt";
CM_ SG_ 1280 veh_cb_cmd_e "Circuit Breaker command from the Vehicle/Tester.";
CM_ SG_ 1536 stack_U_samplingfault_actv_b "BAAT_PACKVOLSAMPINGLOOP_FAULT";
CM_ SG_ 1536 rolling_counter "Message integrity counter.";
CM_ SG_ 1536 pwr_uvp_actv_b "POWERSUPPLY_BMS_UNDERVLT_FAULT";
CM_ SG_ 1536 pwr_ovp_actv_b "POWERSUPPLY_BMS_OVERVLT_FAULT";
CM_ SG_ 1536 pack_uvp_actv_b "Indicates if cell-level over-voltage protection is active.";
CM_ SG_ 1536 pack_T_samplingfault_actv_b "TEMPERATURE_SAMPLINGLINE_OPEN_CKT_FAULT";
CM_ SG_ 1536 pack_ovp_actv_b "Indicates if cell-level over-voltage protection is active.";
CM_ SG_ 1536 pack_deep_chrg_b "Indication that the Pack has been deeply charged.";
CM_ SG_ 1536 otp_actv_b "Indicates if pack over-temperature protection is active.";
CM_ SG_ 1536 ocp_actv_b "Indicates if over-current protection is active.";
CM_ SG_ 1536 inst_I_samplingfault_actv_b "CURRENT_SAMPLINGLINE_OPEN_CKT_FAULT";
CM_ SG_ 1536 dtc_equalize_fail_actv_b "PRECHG_FAULT";
CM_ SG_ 1536 dtc_cb_weld_actv_b "CB_STUCK_CLOSED";
CM_ SG_ 1536 dtc_cb_stuck_open_actv_b "CB_STUCK_OPEN";
CM_ SG_ 1536 cell_uvp_act_b "Indicates if cell-level under-voltage protection is active.";
CM_ SG_ 1536 cell_U_samplingfault_actv_b "BATTTCELL_VOLTAGESAMPLINGLINE_FAULT";
CM_ SG_ 1536 cell_ovp_actv_b "Indicates if cell-level over-voltage protection is active.";
CM_ SG_ 1536 cell_deep_dschrg_b "Indication that the Pack has been deeply discharged.";
CM_ SG_ 1536 cell_deep_chrg_b "Indication that the Pack has been deeply charged.";
CM_ SG_ 1536 can_busoff_actv_b "BMS_CAN_BUSOFF";
CM_ SG_ 1536 cbal_en_b "Indicates if the conditions for cell balancing are active.";
CM_ SG_ 1536 pack_deep_dschrg_b "Indication that the Pack has been deeply discharged.";
CM_ SG_ 1536 nvm_fault_actv_b "BMS_EEPROM_FAULT";
CM_ SG_ 1536 cb_state_e "Circuit Breaker state";
CM_ SG_ 1570 avail_dschrg_60s_PKW "Maximum discharge power available for the next 60 seconds.";
CM_ SG_ 1570 avail_dschrg_60s_IA "Maximum discharge current available for the next 60 seconds.";
CM_ SG_ 1570 avail_chrg_60s_PKW "Maximum charge power available for the next 60 second.";
CM_ SG_ 1570 avail_chrg_60s_IA "Maximum charge current available for the next 60 seconds.";
CM_ SG_ 1569 avail_dschrg_10s_PKW "Maximum discharge power available for the next 10 seconds.";
CM_ SG_ 1569 avail_dschrg_10s_IA "Maximum discharge current available for the next 10 seconds.";
CM_ SG_ 1569 avail_chrg_10s_PKW "Maximum charge power available for the next 10 seconds";
CM_ SG_ 1569 avail_chrg_10s_IA "Maximum charge current available for the next 10 seconds.";
CM_ SG_ 1568 avail_dschrg_1s_PKW "Maximum discharge power available for the next 1 second.";
CM_ SG_ 1568 avail_dschrg_1s_IA "Maximum discharge current available for the next 1 second.";
CM_ SG_ 1568 avail_chrg_1s_PKW "Maximum charge power available for the next 1 second.";
CM_ SG_ 1568 avail_chrg_1s_IA "Maximum charge current available for the next 1 second.";
CM_ SG_ 1585 pwrmon_b "Indicates if the 12V supply  is too low to drive the Circuit Breaker.";
CM_ SG_ 1585 pack_soc_abs_Pct "Absolute pack State of Charge.";
CM_ SG_ 1585 pack_2_T "Pack temperature 2.";
CM_ SG_ 1585 pack_1_T "Pack temperature 1.";
CM_ SG_ 1585 lv_pwr_U "Low voltage (12V) power voltage.";
CM_ SG_ 1585 ign_b "Indicates the value of the IGNITION discrete input.";
CM_ SG_ 1585 hw_ovp_actv_b "Indicates the value of the HWOVP discrete input.";
CM_ SG_ 1585 crash_wake_b "Indicates the value of the CRASH_WAKE discrete input.";
CM_ SG_ 1584 term_U "Voltage between the positive and negtive terminals";
CM_ SG_ 1584 stack_U "Potential between cell 14 positive and cell 1 negative.";
CM_ SG_ 1584 inst_I "Battery current";
CM_ SG_ 417 DCDC_UHV "Voltage measured by the converter at HV terminals£¬aligned with Valeo DC-DC Spec V0.23";
CM_ SG_ 417 DCDC_U14 "Voltage measured by the converter at LV terminals£¬aligned with Valeo DC-DC Spec V0.23";
CM_ SG_ 417 DCDC_TEMP "Converter¡¯s power board temperature.,aligned with Valeo DC-DC Spec V0.23";
CM_ SG_ 417 DCDC_IHV "Current supplied or taken by the converter on HV network (estimated from I14 measurement)£¬aligned with Valeo DC-DC Spec V0.23";
CM_ SG_ 417 DCDC_I14 "Current measured by the converter (LV network side)£¬aligned with Valeo DC-DC Spec V0.23";
CM_ SG_ 416 DCDC_VOLTAGE_STATUS "Voltage status,aligned with Valeo DC-DC Spec V0.23. Not implemented";
CM_ SG_ 416 DCDC_CURRENT_STATUS "Load status, aligned with Valeo DC-DC Spec V0.23. Not implemented";
CM_ SG_ 416 DCDC_PRECH_STATUS "Precharge status";
CM_ SG_ 416 DCDC_MODE "Information related to the converter operating mode, aligned with Valeo DC-DC Spec V0.23. Parial implemented only 0x2, 0x3, 0x4, 0x5, 0x7, 0x8 implememted";
CM_ SG_ 416 DCDC_FAULT_STATUS "Fault status,aligned with Valeo DC-DC Spec V0.23";
CM_ SG_ 416 DCDC_FAULT "Faults detected by the converter,aligned with Valeo DC-DC Spec V0.23. Parial implemented, only OVP and OCP implemented";
CM_ SG_ 688 DCDC_VERSION_REQ "Activate periodic sending of DCDC_VERSION message, aligned with Valeo DC-DC Spec V0.23";
CM_ SG_ 688 DCDC_UREG_REQ "Voltage regulation setpoint (either for LV or HV network voltage regulation regarding the operating mode direct / reverse)";
CM_ SG_ 688 DCDC_UPRECH_REQ "Voltage setpoint for precharge. Not implemented in A sample";
CM_ SG_ 688 DCDC_PRECH_REQ "DCDC precharge command";
CM_ SG_ 688 DCDC_IMAX_REQ "Maximal current that can be taken output network";
CM_ SG_ 688 DCDC_DIRECTION_REQ "Power conversion direction control.";
CM_ SG_ 1366 MASTER_Generator_TrqLimitation "Machine torque limitation in GENERATOR mode";
CM_ SG_ 1366 MASTER_Generator_RegVoltage "Voltage regulation Value in GENERATOR mode";
CM_ SG_ 1366 MASTER_DIS_ExMaxCurrent "Maximum excitation current during discharge";
CM_ SG_ 1366 MASTER_ESA_DurationMax "Maximum duration of ESA";
CM_ SG_ 1366 MASTER_ESA_EndSpeed "Machine end speed for ESA mode";
CM_ SG_ 1366 MASTER_ESA_Speedgradient "Negative speed gradient in ESA mode";
CM_ SG_ 1366 MASTER_ESA_TorqueLimitation "Torque limitation set point in ESA mode";
CM_ BO_ 1620 "Return Machine Inverter Torque data";
CM_ SG_ 1620 SCU_IDC_Current "Continuous side current during Machine Mode";
CM_ SG_ 1620 SCU_Estimated_Torque "Instantaneous estimated torque ";
CM_ BO_ 1364 "Send Machine Inverter Control Request";
CM_ SG_ 1364 MASTER_TRQCTRL_POS_TRQ_LIM "Positive torque limitation in torque control mode";
CM_ SG_ 1364 MASTER_TRQCTRL_NEG_TRQ_LIM "Negative torque limitation in torque control mode";
CM_ SG_ 1364 MASTER_NEGATIVE_TORQUE_GRADIENT "Negative Torque Gradient";
CM_ SG_ 1364 MASTER_POSITIVE_TORQUE_GRADIENT "Positive Torque Gradient";
CM_ SG_ 1364 MASTER_TorqueCtrl_RegTorque "Torque request parameter";
CM_ SG_ 1364 MASTER_MM_REQUEST "Requested Mode";
CM_ BO_ 1619 "Return Machine Inverter Status";
CM_ SG_ 1619 CRANK_POSSIBLE_IF_STOPPED "Engine status for restart need";
CM_ SG_ 1619 SCU_ENA_STATUS "SCU mode enable status";
CM_ SG_ 1619 iBSG_Temperature_Rate "IBSG Temperature Rate";
CM_ SG_ 1619 SCU_Rotor_Speed "Mechanical Machine Speed";
CM_ SG_ 1619 SCU_BUS_VOLTAGE "+BAT48V  storage voltage";
CM_ SG_ 1619 SCU_MM_STATUS "Machine functional status";
BA_DEF_ BO_  "GenMsgILSupport" ENUM  "No","Yes";
BA_DEF_ SG_  "GenSigStartValue" INT 0 0;
BA_DEF_ BO_  "GenMsgSendType" ENUM  "Cyclic";
BA_DEF_ BO_  "GenMsgCycleTime" INT 10 1000;
BA_DEF_  "BusType" STRING ;
BA_DEF_DEF_  "GenMsgILSupport" "Yes";
BA_DEF_DEF_  "GenSigStartValue" 0;
BA_DEF_DEF_  "GenMsgSendType" "Cyclic";
BA_DEF_DEF_  "GenMsgCycleTime" 10;
BA_DEF_DEF_  "BusType" "";
BA_ "BusType" "CAN";
BA_ "GenMsgCycleTime" BO_ 611 100;
BA_ "GenMsgCycleTime" BO_ 613 100;
BA_ "GenMsgCycleTime" BO_ 395 100;
BA_ "GenMsgCycleTime" BO_ 414 100;
BA_ "GenMsgCycleTime" BO_ 612 100;
BA_ "GenMsgCycleTime" BO_ 618 1000;
BA_ "GenMsgCycleTime" BO_ 610 100;
BA_ "GenMsgCycleTime" BO_ 609 100;
BA_ "GenMsgCycleTime" BO_ 560 100;
BA_ "GenMsgCycleTime" BO_ 592 100;
BA_ "GenMsgCycleTime" BO_ 576 100;
BA_ "GenMsgCycleTime" BO_ 512 50;
BA_ "GenMsgCycleTime" BO_ 520 20;
BA_ "GenMsgCycleTime" BO_ 1367 100;
BA_ "GenMsgCycleTime" BO_ 1621 100;
BA_ "GenMsgCycleTime" BO_ 1280 50;
BA_ "GenMsgCycleTime" BO_ 1536 50;
BA_ "GenMsgCycleTime" BO_ 1570 1000;
BA_ "GenMsgCycleTime" BO_ 1569 1000;
BA_ "GenMsgCycleTime" BO_ 1568 100;
BA_ "GenMsgCycleTime" BO_ 1585 50;
BA_ "GenMsgCycleTime" BO_ 1584 50;
BA_ "GenMsgCycleTime" BO_ 416 50;
BA_ "GenSigStartValue" SG_ 304 IMU_YawRt 32768;
BA_ "GenSigStartValue" SG_ 414 APM_Hint_out 14;
BA_ "GenSigStartValue" SG_ 612 PCA_CurrGearSelect 1;
BA_ "GenSigStartValue" SG_ 610 CoPOM_tqElMDesPca 500;
BA_ "GenSigStartValue" SG_ 610 IOT_Tmot 64;
BA_ "GenSigStartValue" SG_ 592 Map_Slope_Second 500;
BA_ "GenSigStartValue" SG_ 576 Map_Slope_Next 500;
BA_ "GenSigStartValue" SG_ 576 Map_Slope_Current 500;
BA_ "GenSigStartValue" SG_ 597 EMS_EngineIntakeAirTemp 53.3333333333333;
BA_ "GenSigStartValue" SG_ 1624 SCU_Negative_Trq_Prediction_10s 550;
BA_ "GenSigStartValue" SG_ 1570 avail_dschrg_60s_PKW 4095;
BA_ "GenSigStartValue" SG_ 1570 avail_dschrg_60s_IA 1023;
BA_ "GenSigStartValue" SG_ 1569 avail_dschrg_10s_PKW 4095;
BA_ "GenSigStartValue" SG_ 1569 avail_dschrg_10s_IA 1023;
BA_ "GenSigStartValue" SG_ 1568 avail_dschrg_1s_PKW 4095;
BA_ "GenSigStartValue" SG_ 1568 avail_dschrg_1s_IA 1023;
BA_ "GenSigStartValue" SG_ 1585 pack_2_T 800;
BA_ "GenSigStartValue" SG_ 1585 pack_1_T 800;
BA_ "GenSigStartValue" SG_ 1584 term_U 15000;
BA_ "GenSigStartValue" SG_ 1584 stack_U 15000;
BA_ "GenSigStartValue" SG_ 417 DCDC_U14 140;
BA_ "GenSigStartValue" SG_ 417 DCDC_TEMP 68;
BA_ "GenSigStartValue" SG_ 417 DCDC_IHV 255;
BA_ "GenSigStartValue" SG_ 417 DCDC_I14 255;
BA_ "GenSigStartValue" SG_ 416 DCDC_PRECH_STATUS 1;
BA_ "GenSigStartValue" SG_ 688 DCDC_UREG_REQ 933.333333333333;
BA_ "GenSigStartValue" SG_ 688 DCDC_UPRECH_REQ 3200;
BA_ "GenSigStartValue" SG_ 1366 MASTER_Generator_TrqLimitation 10;
BA_ "GenSigStartValue" SG_ 1366 MASTER_Generator_RegVoltage 380;
BA_ "GenSigStartValue" SG_ 1366 MASTER_DIS_ExMaxCurrent 20;
BA_ "GenSigStartValue" SG_ 1366 MASTER_ESA_DurationMax 10;
BA_ "GenSigStartValue" SG_ 1366 MASTER_ESA_EndSpeed 10;
BA_ "GenSigStartValue" SG_ 1366 MASTER_ESA_Speedgradient 200;
BA_ "GenSigStartValue" SG_ 1620 SCU_Positive_Trq_Prediction_1s 500;
BA_ "GenSigStartValue" SG_ 1620 SCU_Negative_Trq_Prediction_1s 440;
BA_ "GenSigStartValue" SG_ 1620 SCU_IDC_Current 400;
BA_ "GenSigStartValue" SG_ 1620 SCU_Estimated_Torque 550;
BA_ "GenSigStartValue" SG_ 1364 MASTER_TRQCTRL_POS_TRQ_LIM 30;
BA_ "GenSigStartValue" SG_ 1364 MASTER_TRQCTRL_NEG_TRQ_LIM 30;
BA_ "GenSigStartValue" SG_ 1364 MASTER_NEGATIVE_TORQUE_GRADIENT 10;
BA_ "GenSigStartValue" SG_ 1364 MASTER_POSITIVE_TORQUE_GRADIENT 10;
BA_ "GenSigStartValue" SG_ 1364 MASTER_TorqueCtrl_RegTorque 88;
BA_ "GenSigStartValue" SG_ 1364 MASTER_MM_REQUEST 1;
BA_ "GenSigStartValue" SG_ 1619 SCU_Rotor_Speed 2000;
BA_ "GenSigStartValue" SG_ 1619 SCU_MM_STATUS 16;
VAL_ 395 APM_Mode 15 "error" 3 "Counterforce" 2 "VPP_hold" 1 "VPP" 0 "no_force" ;
VAL_ 395 APM_Hint 4 "old: Multivibration" 3 "old: Counterforce" 2 "old: Double_pulse" 1 "Double_pulse   old: single_pulse" 0 "no_force" ;
VAL_ 395 APM_Angle_SP 0 "Init" ;
VAL_ 414 APM_VPP_Pos 0 "Init" ;
VAL_ 414 APM_SW_release_counter 2 "SW_release_V2" 1 "SW_release_V1" 0 "Init" ;
VAL_ 414 APM_SW_release_costumer 4 "BMW" 3 "DAIMLER" 2 "JLR" 1 "AUDI" 0 "Init" ;
VAL_ 414 APM_ped_angle 0 "Init" ;
VAL_ 414 APM_Over_voltage 1 "Over_voltage" 0 "no_error" ;
VAL_ 414 APM_Over_Temp 1 "Over_temperature" 0 "no_error" ;
VAL_ 414 APM_Mode_out 15 "error" 2 "VPP_hold" 1 "VPP" 0 "no_force" ;
VAL_ 414 APM_Hint_out 15 "error" 14 "Init" 4 "Multivibration" 3 "Counterforce" 2 "Double_Pulse" 1 "Single_pulse" 0 "no_force" ;
VAL_ 414 APM_LOW_voltage 1 "Low_voltage" 0 "Kein_Fehler" ;
VAL_ 414 APM_mech_error 1 "mechanical_error" 0 "no_error" ;
VAL_ 414 APM_CAN_Comm 1 "CAN_communication_error" 0 "no_error" ;
VAL_ 414 APM_cyclic_check 1 "cyclic_check_error" 0 "no_error" ;
VAL_ 414 APM_EEPROM_writing 1 "during_EEPROM_writing" 0 "no_writing" ;
VAL_ 414 APM_electrical_error 1 "Electrical_error" 0 "no_error" ;
VAL_ 414 APM_availability 1 "available" 0 "no_error" ;
VAL_ 609 ssstate_ua 6 "autostopping" 5 "operation" 4 "EngRestart" 3 "staRestart" 2 "stopped" 1 "standby" 0 "reset" ;
VAL_ 512 Camera_LightColor 3 "red light" 2 "yellow light" 1 "green light" 0 "Overrange" ;
VAL_ 1621 SCU_EXC_OPENCIRCUIT_FAULT 1 "Fault" 0 "No fault" ;
VAL_ 1621 SCU_EXC_LATENT_FAULT 1 "Fault" 0 "No fault" ;
VAL_ 1621 SCU_EXC_HSM_FAULT 1 "Fault" 0 "No fault" ;
VAL_ 1621 SCU_CAN_COM_ERROR 1 "Fault" 0 "No fault" ;
VAL_ 1621 SCU_DC_VOLTAGEMEAS_SENSOR_FAULT 1 "Fault" 0 "No fault" ;
VAL_ 1621 SCU_PHX_CURRENT_SENSOR_FAULT 6 "Phase 6 Fault" 5 "Phase 5 Fault" 4 "Phase 4 Fault" 3 "Phase 3 Fault" 2 "Phase 2 Fault" 1 "Phase 1 Fault" 0 "No fault" ;
VAL_ 1621 SCU_MACHINE_TEMP_SENSOR_FAULT 1 "Fault" 0 "No fault" ;
VAL_ 1621 SCU_INVERTER_TEMP_SENSOR_FAULT 1 "Fault" 0 "No fault" ;
VAL_ 1621 SCU_POSITION_SENSORS_FAULT 1 "Fault" 0 "No fault" ;
VAL_ 1621 SCU_STATOR_FAULT 1 "Fault" 0 "No fault" ;
VAL_ 1621 SCU_INVERTER_FAULT 1 "Fault" 0 "No fault" ;
VAL_ 1621 SCU_TORQUE_CTRL_TIMEOUT 1 "Fault" 0 "No fault" ;
VAL_ 1621 SCU_TORQUE_SIGN_FAULT 1 "Fault" 0 "No fault" ;
VAL_ 1621 SCU_TORQUE_LEVEL_FAULT 1 "Fault" 0 "No fault" ;
VAL_ 1621 SCU_ROTOR_OVERCURRENT 1 "Fault" 0 "No fault" ;
VAL_ 1621 SCU_STATOR_OVERCURRENT 6 "Phase 6 Fault" 5 "Phase 5 Fault" 4 "Phase 4 Fault" 3 "Phase 3 Fault" 2 "Phase 2 Fault" 1 "Phase 1 Fault" 0 "No fault" ;
VAL_ 1621 SCU_LOADDUMP 1 "Fault" 0 "No fault" ;
VAL_ 1621 SCU_OVERVOLTAGE 1 "Fault" 0 "No fault" ;
VAL_ 1621 SCU_MOSFET_JUNCTION_PROTECTION 1 "Fault" 0 "No fault" ;
VAL_ 1621 SCU_OVERHEATING 1 "Fault" 0 "No fault" ;
VAL_ 1621 SCU_STARTER_WARNING 1 "Fault" 0 "No fault" ;
VAL_ 1621 SCU_THERMAL_DERATING 1 "Fault" 0 "No fault" ;
VAL_ 1621 SCU_STALLED_ROTOR_PROTECTION 1 "Fault" 0 "No fault" ;
VAL_ 1621 SCU_TORQUE_SUSPENSION 1 "Fault" 0 "No fault" ;
VAL_ 1280 veh_cb_cmd_e 1 "VEH_CB_CMD_CLOSE" 0 "VEH_CB_CMD_OPEN" ;
VAL_ 1536 cb_state_e 2 "CB_STATE_FAULT" 1 "CB_STATE_CLOSED" 0 "CB_STATE_OPEN" ;
VAL_ 1585 wake_b 1 "active" 0 "not active" ;
VAL_ 1585 pwrmon_b 1 "active" 0 "not active" ;
VAL_ 1585 ign_b 1 "active" 0 "not active" ;
VAL_ 1585 hw_ovp_actv_b 1 "active" 0 "not active" ;
VAL_ 1585 crash_wake_b 1 "active" 0 "not active" ;
VAL_ 416 DCDC_VOLTAGE_STATUS 128 "Overvoltage on HV network" 64 "High Voltage on HV network" 32 "Low Voltage  on HV network" 16 "Undervoltage on HV network" 8 "Overvoltage on LV network" 4 "High Voltage on LV network" 2 "Low Voltage on LV network" 1 "Undervoltage on LV network" 0 "No voltage out of range" ;
VAL_ 416 DCDC_CURRENT_STATUS 3 "reserved" 2 "Overcurrent on LV network" 1 "Overcurrent on HV network" 0 "No overload" ;
VAL_ 416 DCDC_PRECH_STATUS 3 "Invalid" 2 "Precharge not in process" 1 "Precharge in process" 0 "Reserved" ;
VAL_ 416 DCDC_MODE 15 "Invalid" 8 "derating due to overtemperature" 7 "Shut down in progress" 6 "OK for extinction" 5 "Autonomous mode " 4 "requested set-point in progress" 3 "Transition to/from conversion" 2 "Idle mode" 1 "Initialization in progress" ;
VAL_ 416 DCDC_FAULT_STATUS 7 "fault1 fault2 and fault3" 6 "fault2 and fault 3" 5 "fault1 and fault3" 4 "fault3 Permanent failure" 3 "fault1 and fault2" 2 "fault2 Temporary failure" 1 "fault1 Power limitation active" 0 "No fault" ;
VAL_ 688 DCDC_VERSION_REQ 1 "Activate VERSION message" 0 "Deactivate VERSION message" ;
VAL_ 688 DCDC_PRECH_REQ 1 "Activate DCDC Precharge Mode" 0 "Deactivate DCDC Precharge Mode" ;
VAL_ 688 DCDC_DIRECTION_REQ 3 "Invalid" 2 "BOOST" 1 "BUCK" 0 "No power conversion requested" ;
VAL_ 1364 MASTER_MM_REQUEST 8 "DISCHARGE" 7 "ESA" 5 "TORQUE_CTRL" 4 "GENERATOR" 1 "NEUTRAL" ;
VAL_ 1619 CRANK_POSSIBLE_IF_STOPPED 1 "ACTIVE" 0 "NOT_ACTIVE" ;
VAL_ 1619 SCU_ENA_STATUS 1 "ACTIVE" 0 "NOT_ACTIVE" ;
VAL_ 1619 SCU_MM_STATUS 131 "DISCHARGE_OUT_OF_RANGE" 130 "DISCHARGE_FAULT" 129 "DISCHARGE_DONE" 128 "DISCHARGE_ACTIVE" 116 "ESA_INHIB" 115 "ESA_OUT_OF_RANGE" 114 " ESA_FAULT" 113 "ESA_DONE" 112 " ESA_ACTIVE" 86 "TORQUE_CTRL_MAX" 85 "TORQUE_CTRL_DERATING" 84 "TORQUE_CTRL_INHIB" 83 "TORQUE_CTRL_OUT_OF_RANGE" 82 "TORQUE_CTRL_FAULT" 81 "TORQUE_CTRL_IDLE" 80 "TORQUE_CTRL_ACTIVE" 68 " GENERATOR_MAX" 67 "GENERATOR_DERATING" 66 "GENERATOR_OUT_OF_RANGE" 65 "GENERATOR_FAULT" 64 "GENERATOR_ACTIVE" 16 "NEUTRAL" ;
